# ESP32-P4 register map
Vendor: ESPRESSIF SYSTEMS (SHANGHAI) CO., LTD.; Series: ESP32 P-Series; File version: 3
CPU: RV32IMAFC r0p0, little endian, no MPU, FPU, 0 interrupt priority bits
Address unit: 32 bits
Registers are 32-bit, read-write, reset 0x0 unless marked. A register's access mark holds for its fields unless they carry their own. Offsets are from the block's base; [hi:lo] are bit positions; lines under a group give offsets from that group; {n}, {i} and the like mark numbered series.

## DMA — DMA (Direct Memory Access) Controller
Base 0x50081000
0x00 ID0 ro
  [31:0] DMAC_ID
0x08 COMPVER0 ro reset 0x3230302A
  [31:0] DMAC_COMPVER
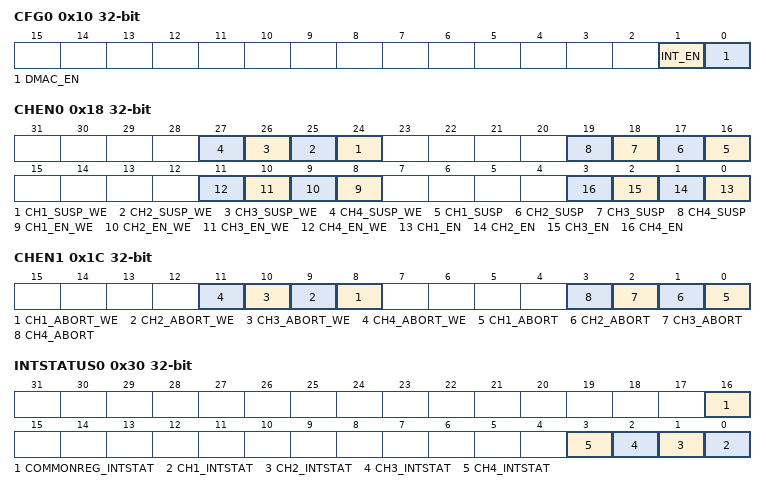
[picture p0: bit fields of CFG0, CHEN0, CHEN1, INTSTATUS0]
0x10 CFG0
  [1] INT_EN, [0] DMAC_EN
0x18 CHEN0 access per field
  [n+23] CH{n}_SUSP_WE wo (n=1..4), [n+15] CH{n}_SUSP rw (n=1..4), [n+7] CH{n}_EN_WE wo (n=1..4), [n-1] CH{n}_EN rw (n=1..4)
0x1C CHEN1 access per field
  [n+7] CH{n}_ABORT_WE wo (n=1..4), [n-1] CH{n}_ABORT rw (n=1..4)
0x30 INTSTATUS0 ro
  [16] COMMONREG_INTSTAT, [n-1] CH{n}_INTSTAT (n=1..4)
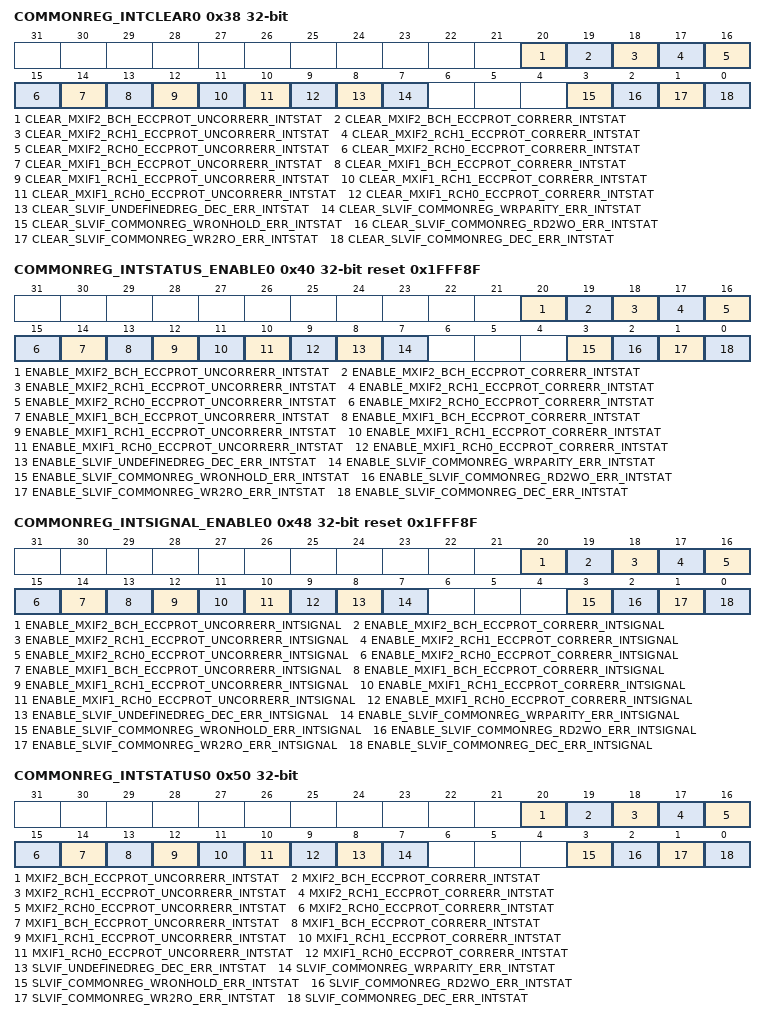
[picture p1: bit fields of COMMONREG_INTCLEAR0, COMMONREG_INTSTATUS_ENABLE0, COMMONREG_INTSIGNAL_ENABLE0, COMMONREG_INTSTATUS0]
0x38 COMMONREG_INTCLEAR0 wo
  [20] CLEAR_MXIF2_BCH_ECCPROT_UNCORRERR_INTSTAT, [19] CLEAR_MXIF2_BCH_ECCPROT_CORRERR_INTSTAT, [18] CLEAR_MXIF2_RCH1_ECCPROT_UNCORRERR_INTSTAT, [17] CLEAR_MXIF2_RCH1_ECCPROT_CORRERR_INTSTAT, [16] CLEAR_MXIF2_RCH0_ECCPROT_UNCORRERR_INTSTAT, [15] CLEAR_MXIF2_RCH0_ECCPROT_CORRERR_INTSTAT, [14] CLEAR_MXIF1_BCH_ECCPROT_UNCORRERR_INTSTAT, [13] CLEAR_MXIF1_BCH_ECCPROT_CORRERR_INTSTAT, [12] CLEAR_MXIF1_RCH1_ECCPROT_UNCORRERR_INTSTAT, [11] CLEAR_MXIF1_RCH1_ECCPROT_CORRERR_INTSTAT, [10] CLEAR_MXIF1_RCH0_ECCPROT_UNCORRERR_INTSTAT, [9] CLEAR_MXIF1_RCH0_ECCPROT_CORRERR_INTSTAT, [8] CLEAR_SLVIF_UNDEFINEDREG_DEC_ERR_INTSTAT, [7] CLEAR_SLVIF_COMMONREG_WRPARITY_ERR_INTSTAT, [3] CLEAR_SLVIF_COMMONREG_WRONHOLD_ERR_INTSTAT, [2] CLEAR_SLVIF_COMMONREG_RD2WO_ERR_INTSTAT, [1] CLEAR_SLVIF_COMMONREG_WR2RO_ERR_INTSTAT, [0] CLEAR_SLVIF_COMMONREG_DEC_ERR_INTSTAT
0x40 COMMONREG_INTSTATUS_ENABLE0 access per field reset 0x1FFF8F
  [20] ENABLE_MXIF2_BCH_ECCPROT_UNCORRERR_INTSTAT ro, [19] ENABLE_MXIF2_BCH_ECCPROT_CORRERR_INTSTAT ro, [18] ENABLE_MXIF2_RCH1_ECCPROT_UNCORRERR_INTSTAT ro, [17] ENABLE_MXIF2_RCH1_ECCPROT_CORRERR_INTSTAT ro, [16] ENABLE_MXIF2_RCH0_ECCPROT_UNCORRERR_INTSTAT ro, [15] ENABLE_MXIF2_RCH0_ECCPROT_CORRERR_INTSTAT ro, [14] ENABLE_MXIF1_BCH_ECCPROT_UNCORRERR_INTSTAT ro, [13] ENABLE_MXIF1_BCH_ECCPROT_CORRERR_INTSTAT ro, [12] ENABLE_MXIF1_RCH1_ECCPROT_UNCORRERR_INTSTAT ro, [11] ENABLE_MXIF1_RCH1_ECCPROT_CORRERR_INTSTAT ro, [10] ENABLE_MXIF1_RCH0_ECCPROT_UNCORRERR_INTSTAT ro, [9] ENABLE_MXIF1_RCH0_ECCPROT_CORRERR_INTSTAT ro, [8] ENABLE_SLVIF_UNDEFINEDREG_DEC_ERR_INTSTAT rw, [7] ENABLE_SLVIF_COMMONREG_WRPARITY_ERR_INTSTAT ro, [3] ENABLE_SLVIF_COMMONREG_WRONHOLD_ERR_INTSTAT rw, [2] ENABLE_SLVIF_COMMONREG_RD2WO_ERR_INTSTAT rw, [1] ENABLE_SLVIF_COMMONREG_WR2RO_ERR_INTSTAT rw, [0] ENABLE_SLVIF_COMMONREG_DEC_ERR_INTSTAT rw
0x48 COMMONREG_INTSIGNAL_ENABLE0 access per field reset 0x1FFF8F
  [20] ENABLE_MXIF2_BCH_ECCPROT_UNCORRERR_INTSIGNAL ro, [19] ENABLE_MXIF2_BCH_ECCPROT_CORRERR_INTSIGNAL ro, [18] ENABLE_MXIF2_RCH1_ECCPROT_UNCORRERR_INTSIGNAL ro, [17] ENABLE_MXIF2_RCH1_ECCPROT_CORRERR_INTSIGNAL ro, [16] ENABLE_MXIF2_RCH0_ECCPROT_UNCORRERR_INTSIGNAL ro, [15] ENABLE_MXIF2_RCH0_ECCPROT_CORRERR_INTSIGNAL ro, [14] ENABLE_MXIF1_BCH_ECCPROT_UNCORRERR_INTSIGNAL ro, [13] ENABLE_MXIF1_BCH_ECCPROT_CORRERR_INTSIGNAL ro, [12] ENABLE_MXIF1_RCH1_ECCPROT_UNCORRERR_INTSIGNAL ro, [11] ENABLE_MXIF1_RCH1_ECCPROT_CORRERR_INTSIGNAL ro, [10] ENABLE_MXIF1_RCH0_ECCPROT_UNCORRERR_INTSIGNAL ro, [9] ENABLE_MXIF1_RCH0_ECCPROT_CORRERR_INTSIGNAL ro, [8] ENABLE_SLVIF_UNDEFINEDREG_DEC_ERR_INTSIGNAL rw, [7] ENABLE_SLVIF_COMMONREG_WRPARITY_ERR_INTSIGNAL ro, [3] ENABLE_SLVIF_COMMONREG_WRONHOLD_ERR_INTSIGNAL rw, [2] ENABLE_SLVIF_COMMONREG_RD2WO_ERR_INTSIGNAL rw, [1] ENABLE_SLVIF_COMMONREG_WR2RO_ERR_INTSIGNAL rw, [0] ENABLE_SLVIF_COMMONREG_DEC_ERR_INTSIGNAL rw
0x50 COMMONREG_INTSTATUS0 ro
  [20] MXIF2_BCH_ECCPROT_UNCORRERR_INTSTAT, [19] MXIF2_BCH_ECCPROT_CORRERR_INTSTAT, [18] MXIF2_RCH1_ECCPROT_UNCORRERR_INTSTAT, [17] MXIF2_RCH1_ECCPROT_CORRERR_INTSTAT, [16] MXIF2_RCH0_ECCPROT_UNCORRERR_INTSTAT, [15] MXIF2_RCH0_ECCPROT_CORRERR_INTSTAT, [14] MXIF1_BCH_ECCPROT_UNCORRERR_INTSTAT, [13] MXIF1_BCH_ECCPROT_CORRERR_INTSTAT, [12] MXIF1_RCH1_ECCPROT_UNCORRERR_INTSTAT, [11] MXIF1_RCH1_ECCPROT_CORRERR_INTSTAT, [10] MXIF1_RCH0_ECCPROT_UNCORRERR_INTSTAT, [9] MXIF1_RCH0_ECCPROT_CORRERR_INTSTAT, [8] SLVIF_UNDEFINEDREG_DEC_ERR_INTSTAT, [7] SLVIF_COMMONREG_WRPARITY_ERR_INTSTAT, [3] SLVIF_COMMONREG_WRONHOLD_ERR_INTSTAT, [2] SLVIF_COMMONREG_RD2WO_ERR_INTSTAT, [1] SLVIF_COMMONREG_WR2RO_ERR_INTSTAT, [0] SLVIF_COMMONREG_DEC_ERR_INTSTAT
0x58 RESET0
  [0] DMAC_RST
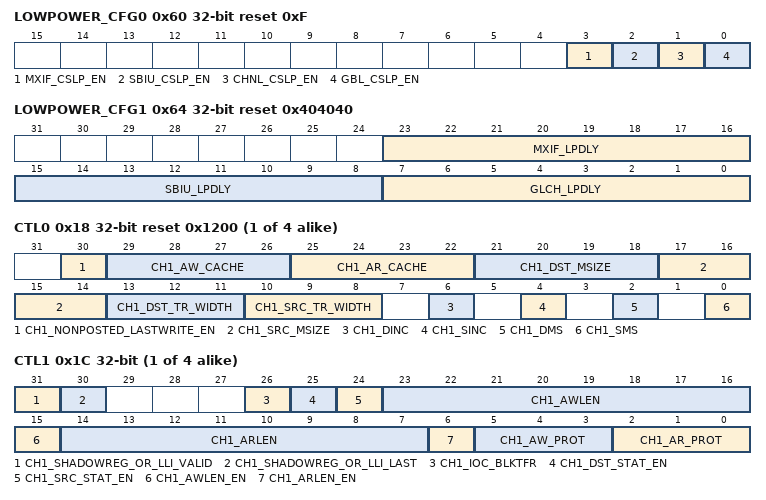
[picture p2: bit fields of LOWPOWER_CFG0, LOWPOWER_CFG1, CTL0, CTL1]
0x60 LOWPOWER_CFG0 reset 0xF
  [3] MXIF_CSLP_EN, [2] SBIU_CSLP_EN, [1] CHNL_CSLP_EN, [0] GBL_CSLP_EN
0x64 LOWPOWER_CFG1 reset 0x404040
  [23:16] MXIF_LPDLY, [15:8] SBIU_LPDLY, [7:0] GLCH_LPDLY
{0x0+0x100*i} CH{i} (i=1..4) group — Cluster CH{i}, containing CH?_SAR0, CH?_SAR1, CH?_DAR0, CH?_DAR1, CH?_BLOCK_TS0, CH?_CTL0, CH?_CTL1, CH?_CFG0, CH?_CFG1, CH?_LLP0, CH?_LLP1, CH?_STATUS0, CH?_STATUS1, CH?_SWHSSRC0, CH?_SWHSDST0, CH?_BLK_TFR_RESUMEREQ0, CH?_AXI_ID0, CH?_AXI_QOS0, CH?_SSTAT0, CH?_DSTAT0, CH?_SSTATAR0, CH?_SSTATAR1, CH?_DSTATAR0, CH?_DSTATAR1, CH?_INTSTATUS_ENABLE0, CH?_INTSTATUS_ENABLE1, CH?_INTSTATUS0, CH?_INTSTATUS1, CH?_INTSIGNAL_ENABLE0, CH?_INTSIGNAL_ENABLE1, CH?_INTCLEAR0, CH?_INTCLEAR1
  0x00 SAR0
    [31:0] CH1_SAR0
  0x04 SAR1
    [31:0] CH1_SAR1
  0x08 DAR0
    [31:0] CH1_DAR0
  0x0C DAR1
    [31:0] CH1_DAR1
  0x10 BLOCK_TS0
    [21:0] CH1_BLOCK_TS
  0x18 CTL0 reset 0x1200
    [30] CH1_NONPOSTED_LASTWRITE_EN, [29:26] CH1_AW_CACHE, [25:22] CH1_AR_CACHE, [21:18] CH1_DST_MSIZE, [17:14] CH1_SRC_MSIZE, [13:11] CH1_DST_TR_WIDTH, [10:8] CH1_SRC_TR_WIDTH, [6] CH1_DINC, [4] CH1_SINC, [2] CH1_DMS, [0] CH1_SMS
  0x1C CTL1
    [31] CH1_SHADOWREG_OR_LLI_VALID, [30] CH1_SHADOWREG_OR_LLI_LAST, [26] CH1_IOC_BLKTFR, [25] CH1_DST_STAT_EN, [24] CH1_SRC_STAT_EN, [23:16] CH1_AWLEN, [15] CH1_AWLEN_EN, [14:7] CH1_ARLEN, [6] CH1_ARLEN_EN, [5:3] CH1_AW_PROT, [2:0] CH1_AR_PROT
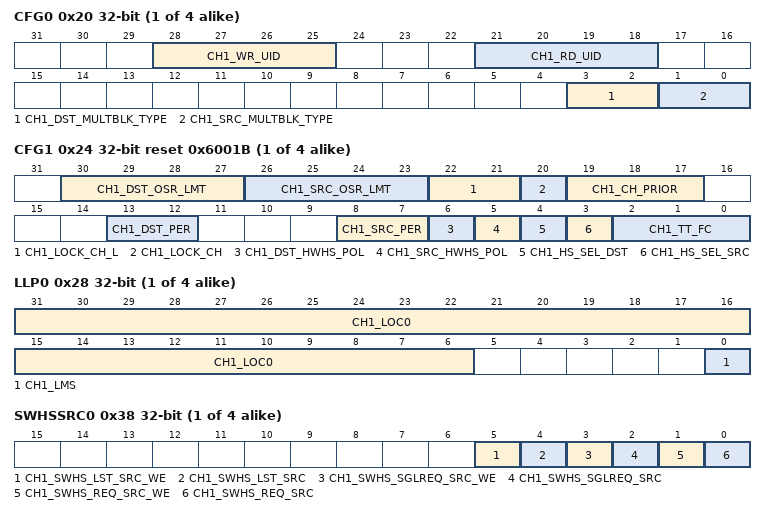
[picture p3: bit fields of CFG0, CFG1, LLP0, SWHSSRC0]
  0x20 CFG0 access per field
    [28:25] CH1_WR_UID ro, [21:18] CH1_RD_UID ro, [3:2] CH1_DST_MULTBLK_TYPE rw, [1:0] CH1_SRC_MULTBLK_TYPE rw
  0x24 CFG1 access per field reset 0x6001B
    [30:27] CH1_DST_OSR_LMT rw, [26:23] CH1_SRC_OSR_LMT rw, [22:21] CH1_LOCK_CH_L ro, [20] CH1_LOCK_CH ro, [19:17] CH1_CH_PRIOR rw, [13:12] CH1_DST_PER rw, [8:7] CH1_SRC_PER rw, [6] CH1_DST_HWHS_POL ro, [5] CH1_SRC_HWHS_POL ro, [4] CH1_HS_SEL_DST rw, [3] CH1_HS_SEL_SRC rw, [2:0] CH1_TT_FC rw
  0x28 LLP0
    [31:6] CH1_LOC0, [0] CH1_LMS
  0x2C LLP1
    [31:0] CH1_LOC1
  0x30 STATUS0 ro
    [21:0] CH1_CMPLTD_BLK_TFR_SIZE
  0x34 STATUS1 ro
    [14:0] CH1_DATA_LEFT_IN_FIFO
  0x38 SWHSSRC0 access per field
    [5] CH1_SWHS_LST_SRC_WE wo, [4] CH1_SWHS_LST_SRC rw, [3] CH1_SWHS_SGLREQ_SRC_WE wo, [2] CH1_SWHS_SGLREQ_SRC rw, [1] CH1_SWHS_REQ_SRC_WE wo, [0] CH1_SWHS_REQ_SRC rw
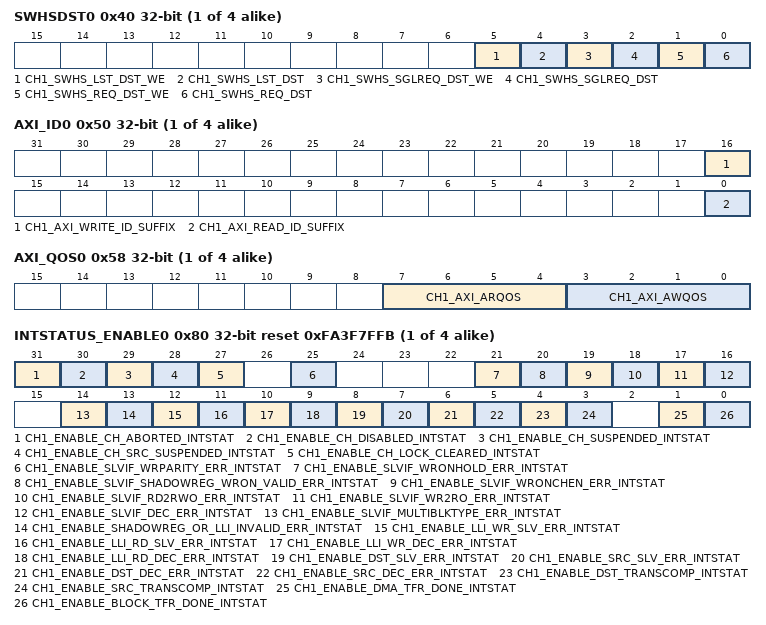
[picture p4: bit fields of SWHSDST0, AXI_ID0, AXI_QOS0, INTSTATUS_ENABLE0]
  0x40 SWHSDST0 access per field
    [5] CH1_SWHS_LST_DST_WE wo, [4] CH1_SWHS_LST_DST rw, [3] CH1_SWHS_SGLREQ_DST_WE wo, [2] CH1_SWHS_SGLREQ_DST rw, [1] CH1_SWHS_REQ_DST_WE wo, [0] CH1_SWHS_REQ_DST rw
  0x48 BLK_TFR_RESUMEREQ0 wo
    [0] CH1_BLK_TFR_RESUMEREQ
  0x50 AXI_ID0
    [16] CH1_AXI_WRITE_ID_SUFFIX, [0] CH1_AXI_READ_ID_SUFFIX
  0x58 AXI_QOS0
    [7:4] CH1_AXI_ARQOS, [3:0] CH1_AXI_AWQOS
  0x60 SSTAT0 ro
    [31:0] CH1_SSTAT
  0x68 DSTAT0 ro
    [31:0] CH1_DSTAT
  0x70 SSTATAR0
    [31:0] CH1_SSTATAR0
  0x74 SSTATAR1
    [31:0] CH1_SSTATAR1
  0x78 DSTATAR0
    [31:0] CH1_DSTATAR0
  0x7C DSTATAR1
    [31:0] CH1_DSTATAR1
  0x80 INTSTATUS_ENABLE0 access per field reset 0xFA3F7FFB
    [31] CH1_ENABLE_CH_ABORTED_INTSTAT rw, [30] CH1_ENABLE_CH_DISABLED_INTSTAT rw, [29] CH1_ENABLE_CH_SUSPENDED_INTSTAT rw, [28] CH1_ENABLE_CH_SRC_SUSPENDED_INTSTAT rw, [27] CH1_ENABLE_CH_LOCK_CLEARED_INTSTAT rw, [25] CH1_ENABLE_SLVIF_WRPARITY_ERR_INTSTAT ro, [21] CH1_ENABLE_SLVIF_WRONHOLD_ERR_INTSTAT rw, [20] CH1_ENABLE_SLVIF_SHADOWREG_WRON_VALID_ERR_INTSTAT rw, [19] CH1_ENABLE_SLVIF_WRONCHEN_ERR_INTSTAT rw, [18] CH1_ENABLE_SLVIF_RD2RWO_ERR_INTSTAT rw, [17] CH1_ENABLE_SLVIF_WR2RO_ERR_INTSTAT rw, [16] CH1_ENABLE_SLVIF_DEC_ERR_INTSTAT rw, [14] CH1_ENABLE_SLVIF_MULTIBLKTYPE_ERR_INTSTAT rw, [13] CH1_ENABLE_SHADOWREG_OR_LLI_INVALID_ERR_INTSTAT rw, [12] CH1_ENABLE_LLI_WR_SLV_ERR_INTSTAT rw, [11] CH1_ENABLE_LLI_RD_SLV_ERR_INTSTAT rw, [10] CH1_ENABLE_LLI_WR_DEC_ERR_INTSTAT rw, [9] CH1_ENABLE_LLI_RD_DEC_ERR_INTSTAT rw, [8] CH1_ENABLE_DST_SLV_ERR_INTSTAT rw, [7] CH1_ENABLE_SRC_SLV_ERR_INTSTAT rw, [6] CH1_ENABLE_DST_DEC_ERR_INTSTAT rw, [5] CH1_ENABLE_SRC_DEC_ERR_INTSTAT rw, [4] CH1_ENABLE_DST_TRANSCOMP_INTSTAT rw, [3] CH1_ENABLE_SRC_TRANSCOMP_INTSTAT rw, [1] CH1_ENABLE_DMA_TFR_DONE_INTSTAT rw, [0] CH1_ENABLE_BLOCK_TFR_DONE_INTSTAT rw
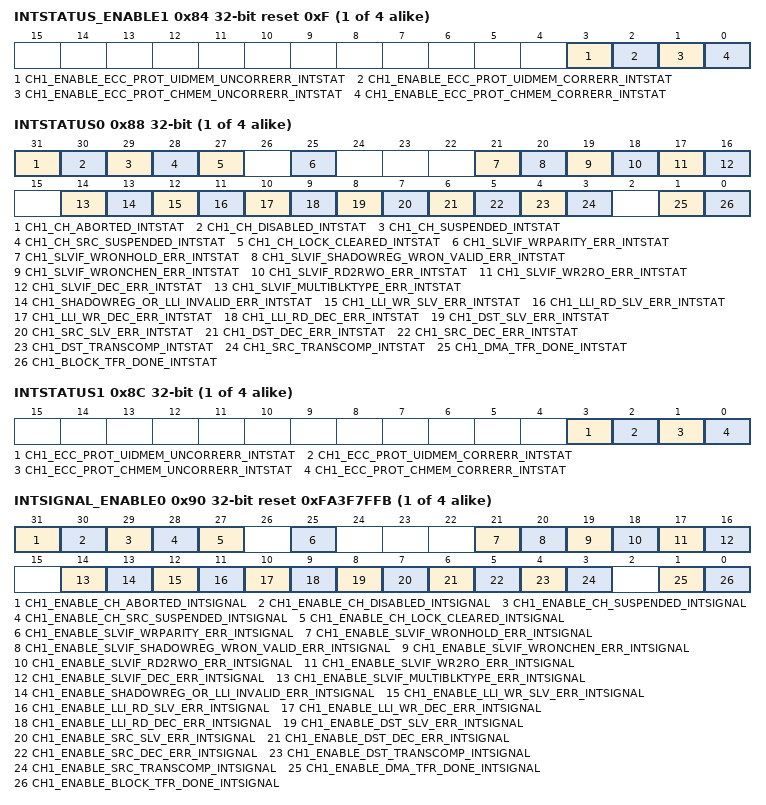
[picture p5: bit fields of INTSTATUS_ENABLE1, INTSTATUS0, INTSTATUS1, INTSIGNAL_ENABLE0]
  0x84 INTSTATUS_ENABLE1 ro reset 0xF
    [3] CH1_ENABLE_ECC_PROT_UIDMEM_UNCORRERR_INTSTAT, [2] CH1_ENABLE_ECC_PROT_UIDMEM_CORRERR_INTSTAT, [1] CH1_ENABLE_ECC_PROT_CHMEM_UNCORRERR_INTSTAT, [0] CH1_ENABLE_ECC_PROT_CHMEM_CORRERR_INTSTAT
  0x88 INTSTATUS0 ro
    [31] CH1_CH_ABORTED_INTSTAT, [30] CH1_CH_DISABLED_INTSTAT, [29] CH1_CH_SUSPENDED_INTSTAT, [28] CH1_CH_SRC_SUSPENDED_INTSTAT, [27] CH1_CH_LOCK_CLEARED_INTSTAT, [25] CH1_SLVIF_WRPARITY_ERR_INTSTAT, [21] CH1_SLVIF_WRONHOLD_ERR_INTSTAT, [20] CH1_SLVIF_SHADOWREG_WRON_VALID_ERR_INTSTAT, [19] CH1_SLVIF_WRONCHEN_ERR_INTSTAT, [18] CH1_SLVIF_RD2RWO_ERR_INTSTAT, [17] CH1_SLVIF_WR2RO_ERR_INTSTAT, [16] CH1_SLVIF_DEC_ERR_INTSTAT, [14] CH1_SLVIF_MULTIBLKTYPE_ERR_INTSTAT, [13] CH1_SHADOWREG_OR_LLI_INVALID_ERR_INTSTAT, [12] CH1_LLI_WR_SLV_ERR_INTSTAT, [11] CH1_LLI_RD_SLV_ERR_INTSTAT, [10] CH1_LLI_WR_DEC_ERR_INTSTAT, [9] CH1_LLI_RD_DEC_ERR_INTSTAT, [8] CH1_DST_SLV_ERR_INTSTAT, [7] CH1_SRC_SLV_ERR_INTSTAT, [6] CH1_DST_DEC_ERR_INTSTAT, [5] CH1_SRC_DEC_ERR_INTSTAT, [4] CH1_DST_TRANSCOMP_INTSTAT, [3] CH1_SRC_TRANSCOMP_INTSTAT, [1] CH1_DMA_TFR_DONE_INTSTAT, [0] CH1_BLOCK_TFR_DONE_INTSTAT
  0x8C INTSTATUS1 ro
    [3] CH1_ECC_PROT_UIDMEM_UNCORRERR_INTSTAT, [2] CH1_ECC_PROT_UIDMEM_CORRERR_INTSTAT, [1] CH1_ECC_PROT_CHMEM_UNCORRERR_INTSTAT, [0] CH1_ECC_PROT_CHMEM_CORRERR_INTSTAT
  0x90 INTSIGNAL_ENABLE0 access per field reset 0xFA3F7FFB
    [31] CH1_ENABLE_CH_ABORTED_INTSIGNAL rw, [30] CH1_ENABLE_CH_DISABLED_INTSIGNAL rw, [29] CH1_ENABLE_CH_SUSPENDED_INTSIGNAL rw, [28] CH1_ENABLE_CH_SRC_SUSPENDED_INTSIGNAL rw, [27] CH1_ENABLE_CH_LOCK_CLEARED_INTSIGNAL rw, [25] CH1_ENABLE_SLVIF_WRPARITY_ERR_INTSIGNAL ro, [21] CH1_ENABLE_SLVIF_WRONHOLD_ERR_INTSIGNAL rw, [20] CH1_ENABLE_SLVIF_SHADOWREG_WRON_VALID_ERR_INTSIGNAL rw, [19] CH1_ENABLE_SLVIF_WRONCHEN_ERR_INTSIGNAL rw, [18] CH1_ENABLE_SLVIF_RD2RWO_ERR_INTSIGNAL rw, [17] CH1_ENABLE_SLVIF_WR2RO_ERR_INTSIGNAL rw, [16] CH1_ENABLE_SLVIF_DEC_ERR_INTSIGNAL rw, [14] CH1_ENABLE_SLVIF_MULTIBLKTYPE_ERR_INTSIGNAL rw, [13] CH1_ENABLE_SHADOWREG_OR_LLI_INVALID_ERR_INTSIGNAL rw, [12] CH1_ENABLE_LLI_WR_SLV_ERR_INTSIGNAL rw, [11] CH1_ENABLE_LLI_RD_SLV_ERR_INTSIGNAL rw, [10] CH1_ENABLE_LLI_WR_DEC_ERR_INTSIGNAL rw, [9] CH1_ENABLE_LLI_RD_DEC_ERR_INTSIGNAL rw, [8] CH1_ENABLE_DST_SLV_ERR_INTSIGNAL rw, [7] CH1_ENABLE_SRC_SLV_ERR_INTSIGNAL rw, [6] CH1_ENABLE_DST_DEC_ERR_INTSIGNAL rw, [5] CH1_ENABLE_SRC_DEC_ERR_INTSIGNAL rw, [4] CH1_ENABLE_DST_TRANSCOMP_INTSIGNAL rw, [3] CH1_ENABLE_SRC_TRANSCOMP_INTSIGNAL rw, [1] CH1_ENABLE_DMA_TFR_DONE_INTSIGNAL rw, [0] CH1_ENABLE_BLOCK_TFR_DONE_INTSIGNAL rw
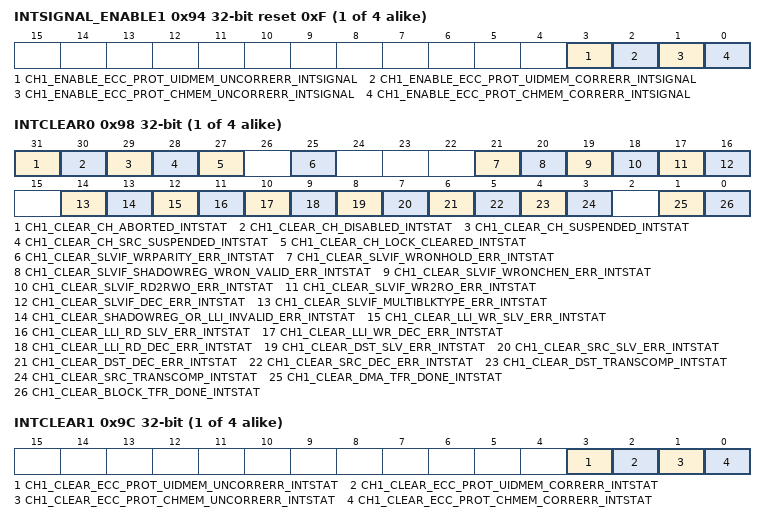
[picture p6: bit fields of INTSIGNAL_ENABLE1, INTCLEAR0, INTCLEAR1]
  0x94 INTSIGNAL_ENABLE1 ro reset 0xF
    [3] CH1_ENABLE_ECC_PROT_UIDMEM_UNCORRERR_INTSIGNAL, [2] CH1_ENABLE_ECC_PROT_UIDMEM_CORRERR_INTSIGNAL, [1] CH1_ENABLE_ECC_PROT_CHMEM_UNCORRERR_INTSIGNAL, [0] CH1_ENABLE_ECC_PROT_CHMEM_CORRERR_INTSIGNAL
  0x98 INTCLEAR0 wo
    [31] CH1_CLEAR_CH_ABORTED_INTSTAT, [30] CH1_CLEAR_CH_DISABLED_INTSTAT, [29] CH1_CLEAR_CH_SUSPENDED_INTSTAT, [28] CH1_CLEAR_CH_SRC_SUSPENDED_INTSTAT, [27] CH1_CLEAR_CH_LOCK_CLEARED_INTSTAT, [25] CH1_CLEAR_SLVIF_WRPARITY_ERR_INTSTAT, [21] CH1_CLEAR_SLVIF_WRONHOLD_ERR_INTSTAT, [20] CH1_CLEAR_SLVIF_SHADOWREG_WRON_VALID_ERR_INTSTAT, [19] CH1_CLEAR_SLVIF_WRONCHEN_ERR_INTSTAT, [18] CH1_CLEAR_SLVIF_RD2RWO_ERR_INTSTAT, [17] CH1_CLEAR_SLVIF_WR2RO_ERR_INTSTAT, [16] CH1_CLEAR_SLVIF_DEC_ERR_INTSTAT, [14] CH1_CLEAR_SLVIF_MULTIBLKTYPE_ERR_INTSTAT, [13] CH1_CLEAR_SHADOWREG_OR_LLI_INVALID_ERR_INTSTAT, [12] CH1_CLEAR_LLI_WR_SLV_ERR_INTSTAT, [11] CH1_CLEAR_LLI_RD_SLV_ERR_INTSTAT, [10] CH1_CLEAR_LLI_WR_DEC_ERR_INTSTAT, [9] CH1_CLEAR_LLI_RD_DEC_ERR_INTSTAT, [8] CH1_CLEAR_DST_SLV_ERR_INTSTAT, [7] CH1_CLEAR_SRC_SLV_ERR_INTSTAT, [6] CH1_CLEAR_DST_DEC_ERR_INTSTAT, [5] CH1_CLEAR_SRC_DEC_ERR_INTSTAT, [4] CH1_CLEAR_DST_TRANSCOMP_INTSTAT, [3] CH1_CLEAR_SRC_TRANSCOMP_INTSTAT, [1] CH1_CLEAR_DMA_TFR_DONE_INTSTAT, [0] CH1_CLEAR_BLOCK_TFR_DONE_INTSTAT
  0x9C INTCLEAR1 wo
    [3] CH1_CLEAR_ECC_PROT_UIDMEM_UNCORRERR_INTSTAT, [2] CH1_CLEAR_ECC_PROT_UIDMEM_CORRERR_INTSTAT, [1] CH1_CLEAR_ECC_PROT_CHMEM_UNCORRERR_INTSTAT, [0] CH1_CLEAR_ECC_PROT_CHMEM_CORRERR_INTSTAT
